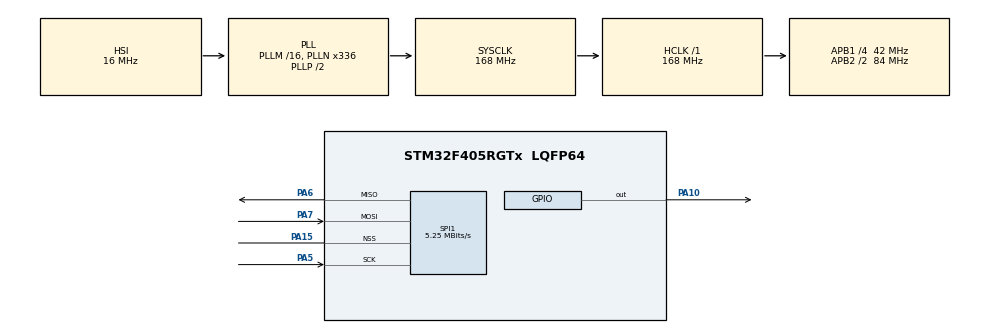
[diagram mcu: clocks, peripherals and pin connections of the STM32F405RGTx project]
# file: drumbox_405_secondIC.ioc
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Dma.Request0=SPI1_RX
Dma.Request1=SPI1_TX
Dma.SPI1_RX.0.Channel=DMA_CHANNEL_3
Dma.SPI1_RX.0.Direction=DMA_PERIPH_TO_MEMORY
Dma.SPI1_RX.0.FIFOMode=DMA_FIFOMODE_ENABLE
Dma.SPI1_RX.0.FIFOThreshold=DMA_FIFO_THRESHOLD_1QUARTERFULL
Dma.SPI1_RX.0.Instance=DMA2_Stream0
Dma.SPI1_RX.0.MemBurst=DMA_MBURST_SINGLE
Dma.SPI1_RX.0.MemDataAlignment=DMA_MDATAALIGN_BYTE
Dma.SPI1_RX.0.MemInc=DMA_MINC_ENABLE
Dma.SPI1_RX.0.Mode=DMA_NORMAL
Dma.SPI1_RX.0.PeriphBurst=DMA_PBURST_SINGLE
Dma.SPI1_RX.0.PeriphDataAlignment=DMA_PDATAALIGN_BYTE
Dma.SPI1_RX.0.PeriphInc=DMA_PINC_DISABLE
Dma.SPI1_RX.0.Priority=DMA_PRIORITY_VERY_HIGH
Dma.SPI1_TX.1.Channel=DMA_CHANNEL_3
Dma.SPI1_TX.1.Direction=DMA_MEMORY_TO_PERIPH
Dma.SPI1_TX.1.FIFOMode=DMA_FIFOMODE_ENABLE
Dma.SPI1_TX.1.FIFOThreshold=DMA_FIFO_THRESHOLD_1QUARTERFULL
Dma.SPI1_TX.1.Instance=DMA2_Stream3
Dma.SPI1_TX.1.MemBurst=DMA_MBURST_SINGLE
Dma.SPI1_TX.1.MemDataAlignment=DMA_MDATAALIGN_BYTE
Dma.SPI1_TX.1.MemInc=DMA_MINC_ENABLE
Dma.SPI1_TX.1.Mode=DMA_NORMAL
Dma.SPI1_TX.1.PeriphBurst=DMA_PBURST_SINGLE
Dma.SPI1_TX.1.PeriphDataAlignment=DMA_PDATAALIGN_BYTE
Dma.SPI1_TX.1.PeriphInc=DMA_PINC_DISABLE
Dma.SPI1_TX.1.Priority=DMA_PRIORITY_VERY_HIGH
Mcu.Family=STM32F4
Mcu.Name=STM32F405RGTx
Mcu.Package=LQFP64
NVIC.DMA2_Stream0_IRQn=true\:0\:1\:false
NVIC.DMA2_Stream3_IRQn=true\:0\:2\:false
NVIC.HASH_RNG_IRQn=true\:0\:7\:true
NVIC.PriorityGroup=NVIC_PRIORITYGROUP_0
NVIC.RCC_IRQn=true\:0\:0\:false
NVIC.SPI1_IRQn=true\:0\:7\:true
PA10.Signal=GPIO_Output
PA13.Mode=Trace-Asynchronous_SW
PA13.Signal=SYS_JTMS-SWDIO
PA14.Mode=Trace-Asynchronous_SW
PA14.Signal=SYS_JTCK-SWCLK
PA15.Mode=NSS_Signal_Hard
PA15.Signal=SPI1_NSS
PA5.GPIO_Mode=GPIO_MODE_AF_PP
PA5.GPIO_PuPd=GPIO_NOPULL
PA5.GPIO_Speed=GPIO_SPEED_HIGH
PA5.Mode=Full_Duplex_Slave
PA5.Signal=SPI1_SCK
PA6.GPIO_Mode=GPIO_MODE_AF_PP
PA6.GPIO_PuPd=GPIO_NOPULL
PA6.GPIO_Speed=GPIO_SPEED_HIGH
PA6.Mode=Full_Duplex_Slave
PA6.Signal=SPI1_MISO
PA7.GPIO_Mode=GPIO_MODE_AF_PP
PA7.GPIO_PuPd=GPIO_NOPULL
PA7.GPIO_Speed=GPIO_SPEED_HIGH
PA7.Mode=Full_Duplex_Slave
PA7.Signal=SPI1_MOSI
PB3.Mode=Trace-Asynchronous_SW
PB3.Signal=SYS_JTDO-SWO
ProjectManager.TargetToolchain=MDK-ARM V5
RCC.48MHZClocksFreq_Value=48000000
RCC.AHBFreq_Value=168000000
RCC.APB1CLKDivider=RCC_HCLK_DIV4
RCC.APB1Freq_Value=42000000
RCC.APB1TimFreq_Value=84000000
RCC.APB2CLKDivider=RCC_HCLK_DIV2
RCC.APB2Freq_Value=84000000
RCC.APB2TimFreq_Value=168000000
RCC.CortexFreq_Value=21000000
RCC.HCLKFreq_Value=168000000
RCC.HSE_VALUE=8000000
RCC.HSI_VALUE=16000000
RCC.I2SClockSource=I2S_CLOCK_EXTERNAL
RCC.LSE_VALUE=32768
RCC.PLLN=336
RCC.PLLQ=7
RCC.PLLSource=RCC_PLLSOURCE_HSE
RCC.SYSCLKFreq_VALUE=168000000
RCC.SYSCLKSource=RCC_SYSCLKSOURCE_PLLCLK
RCC.VCOOutputFreq_Value=336000000
SPI1.BaudRatePrescaler=SPI_BAUDRATEPRESCALER_16
SPI1.CalculateBaudRate=5.25 MBits/s
SPI1.NSS-Full_Duplex_Slave=SPI_NSS_SOFT
SPI1.VirtualNSS=VM_NSSHARD
SPI1.VirtualType=VM_SLAVE
VP_RNG_VS_RNG.Mode=RNG_Activate

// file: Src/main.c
/**
  ******************************************************************************
  * File Name          : main.c
  * Date               : 15/06/2015 14:59:18
  * Description        : Main program body
  ******************************************************************************
  *
  * COPYRIGHT(c) 2015 STMicroelectronics
  *
  * Redistribution and use in source and binary forms, with or without modification,
  * are permitted provided that the following conditions are met:
  *   1. Redistributions of source code must retain the above copyright notice,
  *      this list of conditions and the following disclaimer.
  *   2. Redistributions in binary form must reproduce the above copyright notice,
  *      this list of conditions and the following disclaimer in the documentation
  *      and/or other materials provided with the distribution.
  *   3. Neither the name of STMicroelectronics nor the names of its contributors
  *      may be used to endorse or promote products derived from this software
  *      without specific prior written permission.
  *
  * THIS SOFTWARE IS PROVIDED BY THE COPYRIGHT HOLDERS AND CONTRIBUTORS "AS IS"
  * AND ANY EXPRESS OR IMPLIED WARRANTIES, INCLUDING, BUT NOT LIMITED TO, THE
  * IMPLIED WARRANTIES OF MERCHANTABILITY AND FITNESS FOR A PARTICULAR PURPOSE ARE
  * DISCLAIMED. IN NO EVENT SHALL THE COPYRIGHT HOLDER OR CONTRIBUTORS BE LIABLE
  * FOR ANY DIRECT, INDIRECT, INCIDENTAL, SPECIAL, EXEMPLARY, OR CONSEQUENTIAL
  * DAMAGES (INCLUDING, BUT NOT LIMITED TO, PROCUREMENT OF SUBSTITUTE GOODS OR
  * SERVICES; LOSS OF USE, DATA, OR PROFITS; OR BUSINESS INTERRUPTION) HOWEVER
  * CAUSED AND ON ANY THEORY OF LIABILITY, WHETHER IN CONTRACT, STRICT LIABILITY,
  * OR TORT (INCLUDING NEGLIGENCE OR OTHERWISE) ARISING IN ANY WAY OUT OF THE USE
  * OF THIS SOFTWARE, EVEN IF ADVISED OF THE POSSIBILITY OF SUCH DAMAGE.
  *
  ******************************************************************************
  */

#include "stm32f4xx_hal.h"
#include "dma.h"
#include "rng.h"
#include "spi.h"
#include "gpio.h"

/* USER CODE BEGIN Includes */
#include "waveplayer.h"
#define IC_BUFFERSIZE 4
#define IC_TIMEOUT 2000

/* USER CODE END Includes */

/* USER CODE BEGIN PV */

uint8_t IC_tx[IC_BUFFERSIZE];
uint8_t IC_rx[IC_BUFFERSIZE];
uint8_t counter = 0;

/* USER CODE END PV */

void SystemClock_Config(void);

int main(void)
{

  /* MCU Configuration----------------------------------------------------------*/

  /* Reset of all peripherals, Initializes the Flash interface and the Systick. */
  HAL_Init();

  /* Configure the system clock */
  SystemClock_Config();

  /* Initialize all configured peripherals */
  MX_GPIO_Init();
  MX_DMA_Init();
  MX_RNG_Init();
  MX_SPI1_Init();

  /* USER CODE BEGIN 2 */

	HAL_GPIO_WritePin(GPIOA, GPIO_PIN_10, GPIO_PIN_SET); // dataready pin goes high
	HAL_SPI_TransmitReceive_IT(&hspi1, (uint8_t *)IC_tx, (uint8_t *)IC_rx, IC_BUFFERSIZE);
  /* USER CODE END 2 */

  /* Infinite loop */
  /* USER CODE BEGIN WHILE */
  while (1)
  {
		HAL_GPIO_TogglePin(GPIOA, GPIO_PIN_10);
  /* USER CODE END WHILE */

  /* USER CODE BEGIN 3 */
/*
			  HAL_GPIO_WritePin(GPIOA, GPIO_PIN_10, GPIO_PIN_RESET); // dataready pin goes low - data isn't processed yet
				HAL_SPI_TransmitReceive_IT(&hspi1, (uint8_t *)IC_tx, (uint8_t *)IC_rx, IC_BUFFERSIZE);
				for (int i = 0; i < IC_BUFFERSIZE; i++)
				{
					IC_tx[i] = IC_rx[i];
				}

			  HAL_GPIO_WritePin(GPIOA, GPIO_PIN_10, GPIO_PIN_SET); // dataready pin goes high
		*/
			//counter++;

		//write SPI byte
  }
  /* USER CODE END 3 */

}

/** System Clock Configuration
*/
void SystemClock_Config(void)
{

  RCC_OscInitTypeDef RCC_OscInitStruct;
  RCC_ClkInitTypeDef RCC_ClkInitStruct;

  __PWR_CLK_ENABLE();

  __HAL_PWR_VOLTAGESCALING_CONFIG(PWR_REGULATOR_VOLTAGE_SCALE1);

  RCC_OscInitStruct.OscillatorType = RCC_OSCILLATORTYPE_HSE;
  RCC_OscInitStruct.HSEState = RCC_HSE_OFF;
  RCC_OscInitStruct.PLL.PLLState = RCC_PLL_ON;
  RCC_OscInitStruct.PLL.PLLSource = RCC_PLLSOURCE_HSI;
  RCC_OscInitStruct.PLL.PLLM = 16;
  RCC_OscInitStruct.PLL.PLLN = 336;
  RCC_OscInitStruct.PLL.PLLP = RCC_PLLP_DIV2;
  RCC_OscInitStruct.PLL.PLLQ = 7;
  HAL_RCC_OscConfig(&RCC_OscInitStruct);

  RCC_ClkInitStruct.ClockType = RCC_CLOCKTYPE_SYSCLK|RCC_CLOCKTYPE_PCLK1
                              |RCC_CLOCKTYPE_PCLK2;
  RCC_ClkInitStruct.SYSCLKSource = RCC_SYSCLKSOURCE_PLLCLK;
  RCC_ClkInitStruct.AHBCLKDivider = RCC_SYSCLK_DIV1;
  RCC_ClkInitStruct.APB1CLKDivider = RCC_HCLK_DIV4;
  RCC_ClkInitStruct.APB2CLKDivider = RCC_HCLK_DIV2;
  HAL_RCC_ClockConfig(&RCC_ClkInitStruct, FLASH_LATENCY_5);

}

/* USER CODE BEGIN 4 */

void HAL_SPI_TxRxCpltCallback(SPI_HandleTypeDef *hspi)
{
			for (int i = 0; i < IC_BUFFERSIZE; i++)
			{
				IC_tx[i] = IC_rx[i];
			}
			HAL_GPIO_TogglePin(GPIOA, GPIO_PIN_10);

			HAL_SPI_TransmitReceive_IT(&hspi1, (uint8_t *)IC_tx, (uint8_t *)IC_rx, IC_BUFFERSIZE);
}
/* USER CODE END 4 */

/************************ (C) COPYRIGHT STMicroelectronics *****END OF FILE****/
